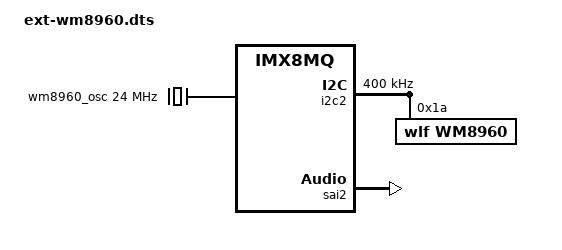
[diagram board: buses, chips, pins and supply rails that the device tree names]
/*
 * Copyright 2023 AVNET
 *
 * This program is free software; you can redistribute it and/or
 * modify it under the terms of the GNU General Public License
 * as published by the Free Software Foundation; either version 2
 * of the License, or (at your option) any later version.
 *
 * This program is distributed in the hope that it will be useful,
 * but WITHOUT ANY WARRANTY; without even the implied warranty of
 * MERCHANTABILITY or FITNESS FOR A PARTICULAR PURPOSE.  See the
 * GNU General Public License for more details.
 */

/dts-v1/;
/plugin/;

#include <dt-bindings/clock/imx8mq-clock.h>
#include "../imx8mq-pinfunc.h"

/* 40-pin extended GPIO, expanded into wm8960 on SAI2 */

&i2c2{
	clock-frequency = <400000>;
	pinctrl-names = "default";
	pinctrl-0 = <&pinctrl_i2c2>;
	status = "okay";

	#address-cells = <1>;
	#size-cells = <0>;
	wm8960: wm8960@1a {
		#sound-dai-cells = <0>;
		compatible = "wlf,wm8960";
		reg = <0x1a>;
		clocks = <&wm8960_osc>;
		clock-names = "mclk";
		wlf,shared-lrclk;
	};
};

&sai2{
	pinctrl-names = "default";
	#sound-dai-cells = <0>;
	pinctrl-0 = <&pinctrl_sai2>;
	assigned-clocks = <&clk IMX8MQ_CLK_SAI2>;
	assigned-clock-parents = <&clk IMX8MQ_AUDIO_PLL1_OUT>;
	assigned-clock-rates = <24576000>;
	status = "okay";
};

&iomuxc {
	pinctrl_i2c2: i2c2grp {
		fsl,pins = <
			MX8MQ_IOMUXC_I2C2_SCL_I2C2_SCL			0x4000007f
			MX8MQ_IOMUXC_I2C2_SDA_I2C2_SDA			0x4000007f
		>;
	};

	pinctrl_sai2: sai2grp {
		fsl,pins = <
			MX8MQ_IOMUXC_SAI2_TXFS_SAI2_TX_SYNC     0xd6
			MX8MQ_IOMUXC_SAI2_TXC_SAI2_TX_BCLK      0xd6
			MX8MQ_IOMUXC_SAI2_RXD0_SAI2_RX_DATA0    0xd6
			MX8MQ_IOMUXC_SAI2_TXD0_SAI2_TX_DATA0    0xd6
		>;
	};
};

/ {
	compatible = "avnet,maaxboard", "fsl,imx8mq";

	fragment@3 {
		target-path = "/";
		__overlay__ {
			sound-wm8960 {
				compatible = "simple-audio-card";
				simple-audio-card,name = "wm8960-sound-audio";
				simple-audio-card,bitclock-master = <&dailink_master>;
				simple-audio-card,frame-master = <&dailink_master>;
				simple-audio-card,format = "i2s";
				status = "okay";
				simple-audio-card,widgets =
						"Microphone", "Mic Jack",
						"Line", "Line In",
						"Line", "Line Out",
						"Speaker", "Speaker",
						"Headphone", "Headphone Jack";
				simple-audio-card,routing =
						"Headphone Jack", "HP_L",
						"Headphone Jack", "HP_R",
						"Speaker", "SPK_LP",
						"Speaker", "SPK_LN",
						"Speaker", "SPK_RP",
						"Speaker", "SPK_RN",
						"LINPUT1", "Mic Jack",
						"LINPUT3", "Mic Jack",
						"RINPUT1", "Mic Jack",
						"RINPUT2", "Mic Jack",
						"Mic Jack", "MICB";

				simple-audio-card,cpu {
					sound-dai = <&sai2>;
				};

				dailink_master: simple-audio-card,codec {
					sound-dai = <&wm8960>;
					clocks = <&wm8960_osc>;
				};
			};

			wm8960_osc: wm8960_mclk {
					compatible = "fixed-clock";
					#clock-cells = <0>;
					clock-frequency = <24000000>;
					clock-output-names = "wm8960-mclk";
			};
		};
	};
};
